# A34L71x register map
Vendor: ABOV Semiconductor Co., Ltd.; File version: 1.0
CPU: CM4 r0p1, little endian, MPU, FPU, VTOR, 4 interrupt priority bits
Registers are 32-bit, read-write, reset 0x0 unless marked. A register's access mark holds for its fields unless they carry their own. Offsets are from the block's base; [hi:lo] are bit positions; {n}, {i} and the like mark numbered series; 'fields as' and 'values as' point back to an identical list.

## ADC — 12-BIT A/D CONVERTER
Base 0x51005000
Same registers: ADC0 0x41005000, ADC1 0x41005100
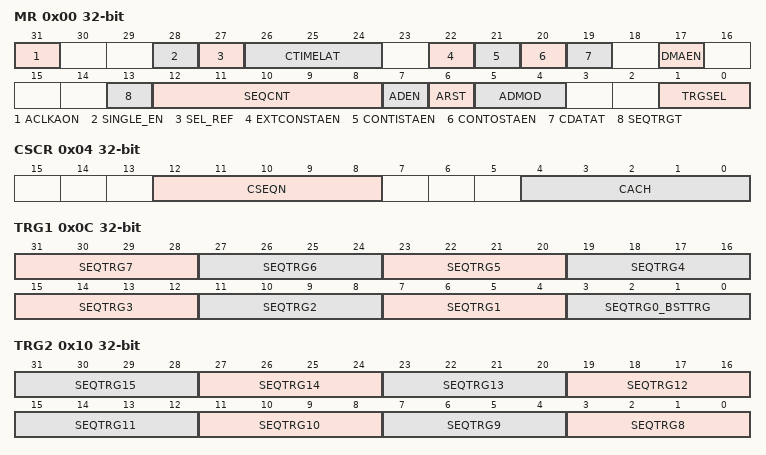
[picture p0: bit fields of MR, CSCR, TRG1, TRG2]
0x00 MR — ADC mode register
  [31] ACLKAON — ADC clock always on control
    0=AUTO (ADC clock auto control); 1=ALWAYS (ADC clock always on enable)
  [28] SINGLE_EN — Single-end input mode
    0=Differential input mode; 1=Single-end input mode
  [27] SEL_REF — SEL_REF control
    0=Disable; 1=Enable
  [26:24] CTIMELAT — conversion time latency cycle param
  [22] EXTCONSTAEN — ADC dual mode enable bit
  [21] CONTISTAEN — Continuous start enable (intput mode)
  [20] CONTOSTAEN — Continuous start enable (output mode)
  [19] CDATAT — Conversion data offset alignment
    0=Bit_15_4 (Data bit 15~4); 1=Bit_11_0 (Data bit 11~0)
  [17] DMAEN — DMA enable bit (This bit must be set if ADCEN = 1.)
    0=Disable (DMA Disable); 1=Enable (DMA Enable)
  [13] SEQTRGT — Trigger pending type control in sequential mode
  [12:8] SEQCNT — Number of conversions in a sequence
  [7] ADEN — ADC enable bit
    0=Disable ADC; 1=Enable ADC
  [6] ARST — Setting bit to restart at the end of the sequence
    0=STOP (after ending, STOP); 1=RESTART (After ending, restart)
  [5:4] ADMOD — ADC mode selection bit
    0=Single_Sequencial Conversion Mode; 1=Burst Conversion Mode; 2=Multiple Conversion Mode
  [1:0] TRGSEL — Trigger selection bit
    0=Soft_TRG (Software Trigger Only); 1=TIMER (TIMER event trigger)
0x04 CSCR — ADC current sequence/channel register
  [12:8] CSEQN ro — Current sequence number
    {v}=Sequence{v} (Current Sequence {v}) (v=0..25)
  [4:0] CACH ro — Current active channel
    {v}=CH{v} (ADC Channel active is {v}) (v=0..23)
0x08 CCR — ADC clock control register
  [14:8] CLKDIV — ADC clock division ratio value bit
0x0C TRG1 — ADC trigger select 1 register
  [all] fields
    {v}=Source_{v} (TIMER {v}) (v=0..7); 15=Source_15 (ASTART)
  [4n+3:4n] SEQTRG{n} (n=1..7) — {n+1}th sequence trigger source
  [3:0] SEQTRG0_BSTTRG — 1th sequence trigger source, Burst conversion trigger source
0x10 TRG2 — ADC trigger select 2 register
  [4n-29:4n-32] SEQTRG{n} (n=8..15) — {n+1}th sequence trigger source
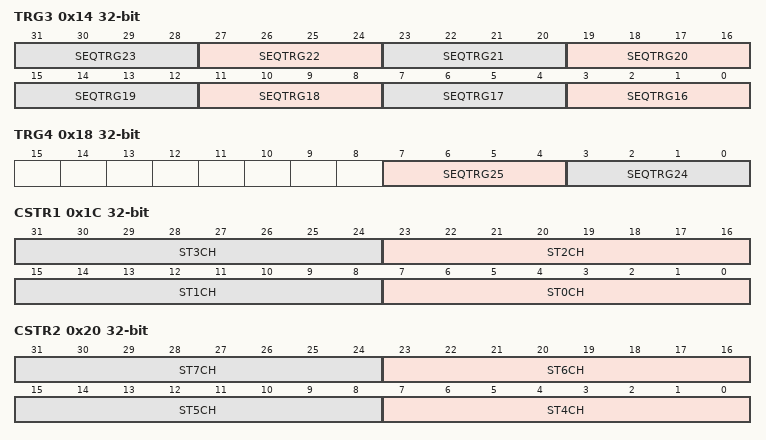
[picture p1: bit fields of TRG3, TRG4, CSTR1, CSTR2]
0x14 TRG3 — ADC trigger select 3 register
  [4n-61:4n-64] SEQTRG{n} (n=16..23) — {n+1}th sequence trigger source
0x18 TRG4 — ADC trigger select 4 register
  [7:4] SEQTRG25 — 26th sequence trigger source
  [3:0] SEQTRG24 — 25th sequence trigger source
0x1C CSTR1 — ADC channel sampling time register 1
  [8n+7:8n] ST{n}CH (n=0..3) — {n+1}th Conversion Sequence Channel sampling time
0x20 CSTR2 — ADC channel sampling time register 2
  [8n-25:8n-32] ST{n}CH (n=4..7) — {n+1}th Conversion Sequence Channel sampling time
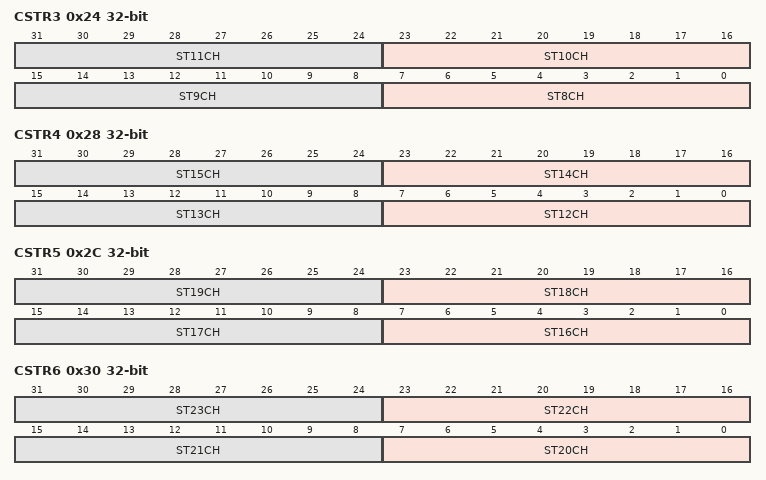
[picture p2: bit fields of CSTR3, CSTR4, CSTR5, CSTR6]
0x24 CSTR3 — ADC channel sampling time register 3
  [8n-57:8n-64] ST{n}CH (n=8..11) — {n+1}th Conversion Sequence Channel sampling time
0x28 CSTR4 — ADC channel sampling time register 4
  [8n-89:8n-96] ST{n}CH (n=12..15) — {n+1}th Conversion Sequence Channel sampling time
0x2C CSTR5 — ADC channel sampling time register 5
  [8n-121:8n-128] ST{n}CH (n=16..19) — {n+1}th Conversion Sequence Channel sampling time
0x30 CSTR6 — ADC channel sampling time register 6
  [8n-153:8n-160] ST{n}CH (n=20..23) — {n+1}th Conversion Sequence Channel sampling time
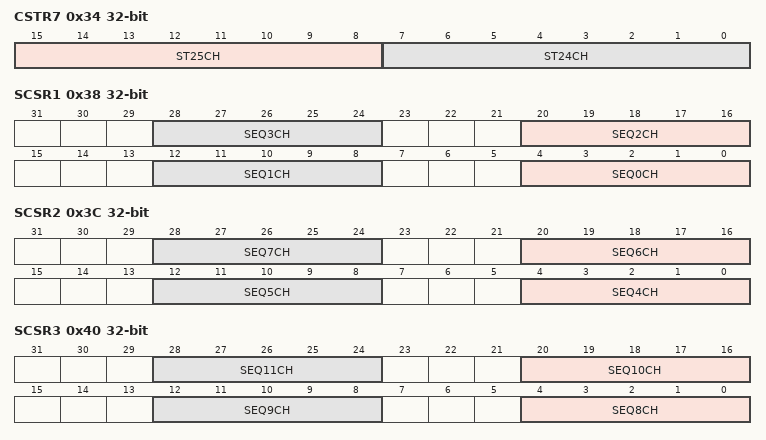
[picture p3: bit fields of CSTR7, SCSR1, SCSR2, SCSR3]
0x34 CSTR7 — ADC channel sampling time register 7
  [15:8] ST25CH — 26th Conversion Sequence Channel sampling time
  [7:0] ST24CH — 25th Conversion Sequence Channel sampling time
0x38 SCSR1 — ADC Channel Selection Register 1
  [8n+4:8n] SEQ{n}CH (n=0..3) — {n+1}th conversion sequence channel selection
0x3C SCSR2 — ADC Channel Selection Register 2
  [8n-28:8n-32] SEQ{n}CH (n=4..7) — {n+1}th conversion sequence channel selection
0x40 SCSR3 — ADC Channel Selection Register 3
  [8n-60:8n-64] SEQ{n}CH (n=8..11) — {n+1}th conversion sequence channel selection
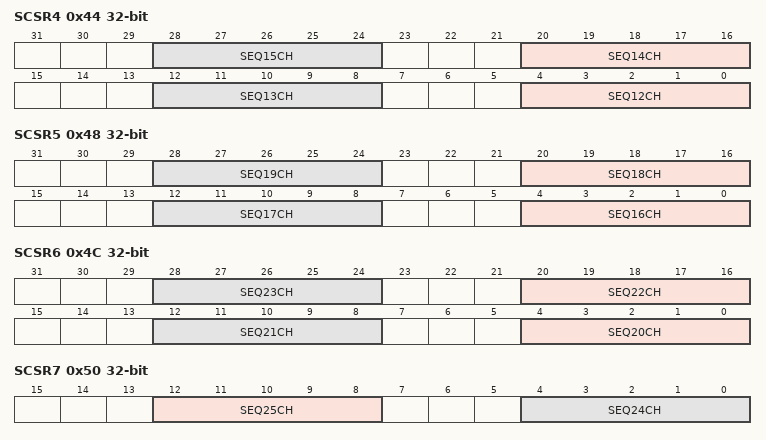
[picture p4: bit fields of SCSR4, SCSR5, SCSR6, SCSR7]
0x44 SCSR4 — ADC Channel Selection Register 4
  [8n-92:8n-96] SEQ{n}CH (n=12..15) — {n+1}th conversion sequence channel selection
0x48 SCSR5 — ADC Channel Selection Register 5
  [8n-124:8n-128] SEQ{n}CH (n=16..19) — {n+1}th conversion sequence channel selection
0x4C SCSR6 — ADC Channel Selection Register 6
  [8n-156:8n-160] SEQ{n}CH (n=20..23) — {n+1}th conversion sequence channel selection
0x50 SCSR7 — ADC Channel Selection Register 7
  [12:8] SEQ25CH — 26th conversion sequence channel selection
  [4:0] SEQ24CH — 25th conversion sequence channel selection
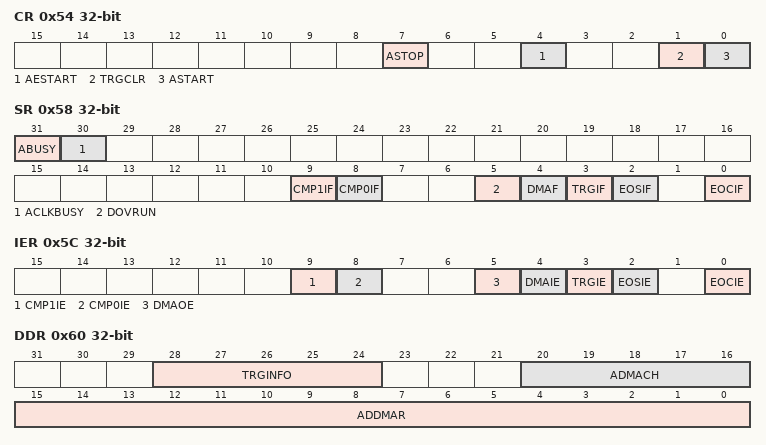
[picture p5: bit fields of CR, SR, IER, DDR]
0x54 CR — ADC control register
  [7] ASTOP wo — ADC STOP bit
  [4] AESTART — ADC all START bit
  [1] TRGCLR — ADC all trigger flags clear option
  [0] ASTART — ADC START Bit
0x58 SR — ADC Status Register
  [31] ABUSY ro — ADC busy status
  [30] ACLKBUSY ro — ADC Clock busy status
  [9] CMP1IF — Compare 1 interrupt flag bit
  [8] CMP0IF — Compare 0 interrupt flag bit
  [5] DOVRUN ro — DMA overrun flag
  [4] DMAF ro — DMA done received flag (DMA transfer is completed.)
  [3] TRGIF — ADC trigger interrupt flag
  [2] EOSIF — Sequence end interrupt flag
  [0] EOCIF — Sequence conversion end interrupt flag
0x5C IER — ADC Interrupt Enable Register
  [9] CMP1IE — Compare 1 event Interrupt Enable
    0=Disable (Compare 1 event Interrupt Disable); 1=Enable (Compare 1 event Interrupt Enable)
  [8] CMP0IE — Compare 0 event interrupt enable
    0=Disable (Compare 0 event Interrupt Disable); 1=Enable (Compare 0 event Interrupt Enable)
  [5] DMAOE — DMA Overrun Interrupt Enable
    0=Disable (DMA Overrun Interrupt Disable); 1=Enable (DMA Overrun Interrupt Enable)
  [4] DMAIE — DMA done interrupt enable
    0=Disable (DMA Interrupt Disable); 1=Enable (DMA Interrupt Enable)
  [3] TRGIE — ADC trigger conversion interrupt enable
    0=Disable (ADC Trigger Conversion Interrupt Disable); 1=Enable (ADC Trigger Conversion Interrupt Enable)
  [2] EOSIE — ADC sequence conversion interrupt enable
    0=Disable (ADC Sequence Conversion Interrupt Disable); 1=Enable (ADC Sequence Conversion Interrupt Enable)
  [0] EOCIE — ADC single conversion interrupt
    0=Disable (ADC Single Conversion Interrupt Disable); 1=Enable (ADC Single Conversion Interrupt Enable)
0x60 DDR ro — ADC DMA data register
  [28:24] TRGINFO — ADC Trigger Information
  [20:16] ADMACH — DMA ADC channel indicator
  [15:0] ADDMAR — DMA ADC conversion result data (12-bit)
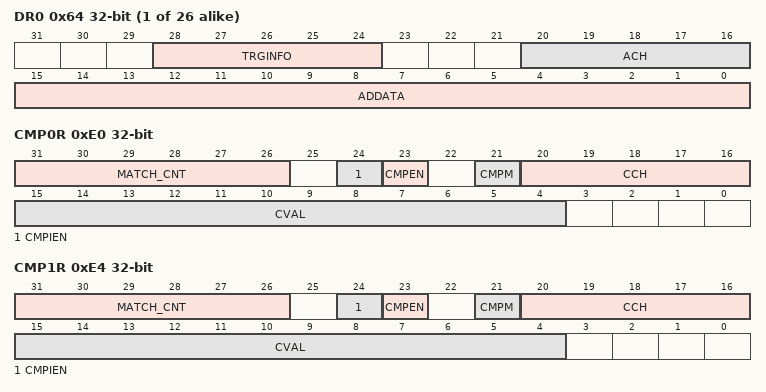
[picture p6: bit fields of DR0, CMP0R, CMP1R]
{0x64+4i} DR{i} (i=0..25) — ADC Data Register {i}
  [28:24] TRGINFO ro — ADC Trigger Information
  [20:16] ACH ro — ADC Channel Information
  [15:0] ADDATA ro — ADC Channel Data (12-bit)
0xE0 CMP0R — ADC Comparator 0 control Register
  [31:26] MATCH_CNT — Interrupt is generated only when ADC data compare data meets the condition (MATCHCNT+1) consecutively.
  [24] CMPIEN — Compare Interrupt Enable Bit
    0=Disable compare interrupt; 1=Enable Compare interrupt
  [23] CMPEN — Compare operation enable bit
    0=Disable compare; 1=Enable compare
  [21] CMPM — ADC compare mode bit
    0=HIGHER (If ADC value is higher than CVAL value, compare output is high); 1=LOWER (If the ADC value is lower than the CVAL value, compare output is high)
  [20:16] CCH — Compare Channel
    {v}=CH{v} (ADC Channel {v}) (v=0..23)
  [15:4] CVAL — Compare value bit
0xE4 CMP1R — ADC Comparator 1 control Register
  [31:26] MATCH_CNT — Interrupt is generated only when ADC data compare data meets the condition (MATCHCNT+1) consecutively.
  [24] CMPIEN — Compare interrupt enable bit
    0=Disable compare interrupt; 1=Enable Compare interrupt
  [23] CMPEN — Compare operation enable bit
    0=Disable compare; 1=Enable compare
  [21] CMPM — ADC compare mode bit
    values as CMP0R.CMPM
  [20:16] CCH — Compare channel
    {v}=CH{v} (ADC Channel {v}) (v=0..23)
  [15:4] CVAL — Compare value bit
